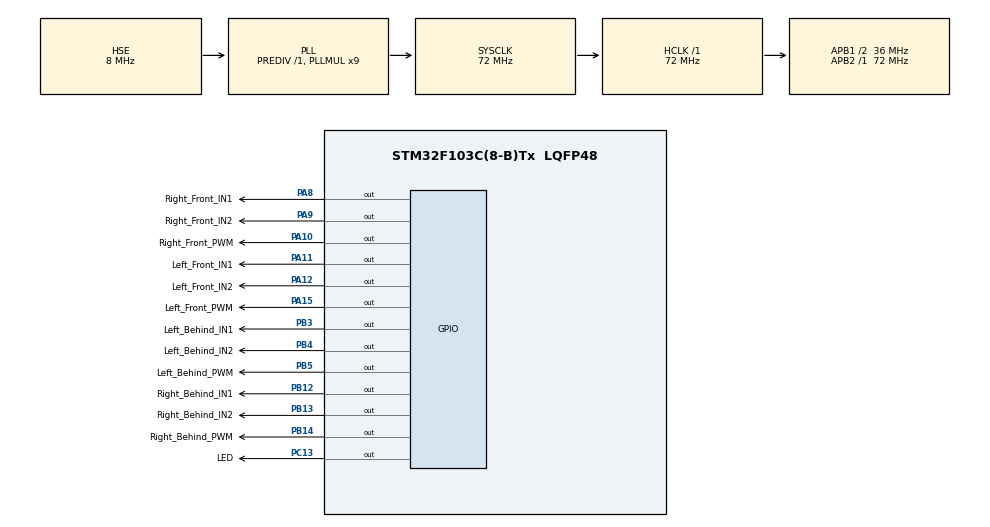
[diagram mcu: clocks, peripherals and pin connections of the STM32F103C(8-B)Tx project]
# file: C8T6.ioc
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Mcu.Family=STM32F1
Mcu.Name=STM32F103C(8-B)Tx
Mcu.Package=LQFP48
NVIC.PriorityGroup=NVIC_PRIORITYGROUP_4
NVIC.TIM2_IRQn=true\:0\:0\:false\:false\:true\:true\:true\:true
NVIC.TIM3_IRQn=true\:0\:0\:false\:false\:true\:true\:true\:true
PA10.GPIO_Label=Right_Front_PWM
PA10.GPIO_PuPd=GPIO_PULLUP
PA10.GPIO_Speed=GPIO_SPEED_FREQ_HIGH
PA10.PinState=GPIO_PIN_SET
PA10.Signal=GPIO_Output
PA11.GPIO_Label=Left_Front_IN1
PA11.Signal=GPIO_Output
PA12.GPIO_Label=Left_Front_IN2
PA12.Signal=GPIO_Output
PA13.Mode=Serial_Wire
PA13.Signal=SYS_JTMS-SWDIO
PA14.Mode=Serial_Wire
PA14.Signal=SYS_JTCK-SWCLK
PA15.GPIO_Label=Left_Front_PWM
PA15.Signal=GPIO_Output
PA8.GPIO_Label=Right_Front_IN1
PA8.GPIO_ModeDefaultOutputPP=GPIO_MODE_OUTPUT_PP
PA8.GPIO_PuPd=GPIO_PULLUP
PA8.GPIO_Speed=GPIO_SPEED_FREQ_HIGH
PA8.PinState=GPIO_PIN_SET
PA8.Signal=GPIO_Output
PA9.GPIO_Label=Right_Front_IN2
PA9.GPIO_ModeDefaultOutputPP=GPIO_MODE_OUTPUT_PP
PA9.GPIO_PuPd=GPIO_PULLUP
PA9.GPIO_Speed=GPIO_SPEED_FREQ_HIGH
PA9.PinState=GPIO_PIN_SET
PA9.Signal=GPIO_Output
PB12.GPIO_Label=Right_Behind_IN1
PB12.GPIO_ModeDefaultOutputPP=GPIO_MODE_OUTPUT_PP
PB12.GPIO_PuPd=GPIO_PULLUP
PB12.GPIO_Speed=GPIO_SPEED_FREQ_HIGH
PB12.PinState=GPIO_PIN_SET
PB12.Signal=GPIO_Output
PB13.GPIO_Label=Right_Behind_IN2
PB13.GPIO_ModeDefaultOutputPP=GPIO_MODE_OUTPUT_PP
PB13.GPIO_PuPd=GPIO_PULLUP
PB13.GPIO_Speed=GPIO_SPEED_FREQ_HIGH
PB13.PinState=GPIO_PIN_SET
PB13.Signal=GPIO_Output
PB14.GPIO_Label=Right_Behind_PWM
PB14.GPIO_ModeDefaultOutputPP=GPIO_MODE_OUTPUT_PP
PB14.GPIO_PuPd=GPIO_PULLUP
PB14.GPIO_Speed=GPIO_SPEED_FREQ_HIGH
PB14.PinState=GPIO_PIN_SET
PB14.Signal=GPIO_Output
PB3.GPIO_Label=Left_Behind_IN1
PB3.Signal=GPIO_Output
PB4.GPIO_Label=Left_Behind_IN2
PB4.Signal=GPIO_Output
PB5.GPIO_Label=Left_Behind_PWM
PB5.Signal=GPIO_Output
PC13-TAMPER-RTC.GPIO_Label=LED
PC13-TAMPER-RTC.GPIO_ModeDefaultOutputPP=GPIO_MODE_OUTPUT_PP
PC13-TAMPER-RTC.GPIO_PuPd=GPIO_PULLUP
PC13-TAMPER-RTC.GPIO_Speed=GPIO_SPEED_FREQ_HIGH
PC13-TAMPER-RTC.PinState=GPIO_PIN_SET
PC13-TAMPER-RTC.Signal=GPIO_Output
PC14-OSC32_IN.Mode=LSE-External-Oscillator
PC14-OSC32_IN.Signal=RCC_OSC32_IN
PC15-OSC32_OUT.Mode=LSE-External-Oscillator
PC15-OSC32_OUT.Signal=RCC_OSC32_OUT
PD0-OSC_IN.Mode=HSE-External-Oscillator
PD0-OSC_IN.Signal=RCC_OSC_IN
PD1-OSC_OUT.Mode=HSE-External-Oscillator
PD1-OSC_OUT.Signal=RCC_OSC_OUT
ProjectManager.HeapSize=0x200
ProjectManager.StackSize=0x400
ProjectManager.TargetToolchain=MDK-ARM V5.32
RCC.AHBFreq_Value=72000000
RCC.APB1CLKDivider=RCC_HCLK_DIV2
RCC.APB1Freq_Value=36000000
RCC.APB1TimFreq_Value=72000000
RCC.APB2Freq_Value=72000000
RCC.APB2TimFreq_Value=72000000
RCC.HCLKFreq_Value=72000000
RCC.PLLMUL=RCC_PLL_MUL9
RCC.PLLSourceVirtual=RCC_PLLSOURCE_HSE
RCC.SYSCLKFreq_VALUE=72000000
RCC.SYSCLKSource=RCC_SYSCLKSOURCE_PLLCLK
RCC.USBFreq_Value=72000000
TIM2.AutoReloadPreload=TIM_AUTORELOAD_PRELOAD_ENABLE
TIM2.Period=100-1
TIM2.Prescaler=720-1
TIM3.AutoReloadPreload=TIM_AUTORELOAD_PRELOAD_ENABLE
TIM3.Period=1000-1
TIM3.Prescaler=7200-1
VP_TIM2_VS_ClockSourceINT.Mode=Internal
VP_TIM3_VS_ClockSourceINT.Mode=Internal
board=custom

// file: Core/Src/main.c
/* USER CODE BEGIN Header */
/**
  ******************************************************************************
  * @file           : main.c
  * @brief          : Main program body
  ******************************************************************************
  * @attention
  *
  * Copyright (c) 2023 STMicroelectronics.
  * All rights reserved.
  *
  * This software is licensed under terms that can be found in the LICENSE file
  * in the root directory of this software component.
  * If no LICENSE file comes with this software, it is provided AS-IS.
  *
  ******************************************************************************
  */
/* USER CODE END Header */
#include "main.h"
#include "tim.h"
#include "gpio.h"

/* USER CODE BEGIN Includes */
#include "include.h"
/* USER CODE END Includes */

void SystemClock_Config(void);

int main(void)
{

  /* MCU Configuration--------------------------------------------------------*/

  /* Reset of all peripherals, Initializes the Flash interface and the Systick. */
  HAL_Init();

  /* Configure the system clock */
  SystemClock_Config();

  /* Initialize all configured peripherals */
  MX_GPIO_Init();
  MX_TIM2_Init();
  MX_TIM3_Init();
  /* USER CODE BEGIN 2 */
       Co_main();
  /* USER CODE END 2 */

  /* Infinite loop */
  /* USER CODE BEGIN WHILE */
  while (1)
  {
      Co_while_main();
    /* USER CODE END WHILE */

  }
}

void SystemClock_Config(void)
{
  RCC_OscInitTypeDef RCC_OscInitStruct = {0};
  RCC_ClkInitTypeDef RCC_ClkInitStruct = {0};

  /** Initializes the RCC Oscillators according to the specified parameters
  * in the RCC_OscInitTypeDef structure.
  */
  RCC_OscInitStruct.OscillatorType = RCC_OSCILLATORTYPE_HSE;
  RCC_OscInitStruct.HSEState = RCC_HSE_ON;
  RCC_OscInitStruct.HSEPredivValue = RCC_HSE_PREDIV_DIV1;
  RCC_OscInitStruct.HSIState = RCC_HSI_ON;
  RCC_OscInitStruct.PLL.PLLState = RCC_PLL_ON;
  RCC_OscInitStruct.PLL.PLLSource = RCC_PLLSOURCE_HSE;
  RCC_OscInitStruct.PLL.PLLMUL = RCC_PLL_MUL9;
  if (HAL_RCC_OscConfig(&RCC_OscInitStruct) != HAL_OK)
  {
    Error_Handler();
  }

  /** Initializes the CPU, AHB and APB buses clocks
  */
  RCC_ClkInitStruct.ClockType = RCC_CLOCKTYPE_HCLK|RCC_CLOCKTYPE_SYSCLK
                              |RCC_CLOCKTYPE_PCLK1|RCC_CLOCKTYPE_PCLK2;
  RCC_ClkInitStruct.SYSCLKSource = RCC_SYSCLKSOURCE_PLLCLK;
  RCC_ClkInitStruct.AHBCLKDivider = RCC_SYSCLK_DIV1;
  RCC_ClkInitStruct.APB1CLKDivider = RCC_HCLK_DIV2;
  RCC_ClkInitStruct.APB2CLKDivider = RCC_HCLK_DIV1;

  if (HAL_RCC_ClockConfig(&RCC_ClkInitStruct, FLASH_LATENCY_2) != HAL_OK)
  {
    Error_Handler();
  }
}

void Error_Handler(void)
{
  __disable_irq();
  while (1)
  {
  }
}
